# ATmega32C1 device description
Architecture: AVR8; Family: megaAVR
Registers are 8-bit, access not given, no defined reset value unless marked. A register's access mark holds for its fields unless they carry their own. Offsets are from the block's base; [hi:lo] are bit positions.

## LINUART — Local Interconnect Network
Instances: LINUART 0x00
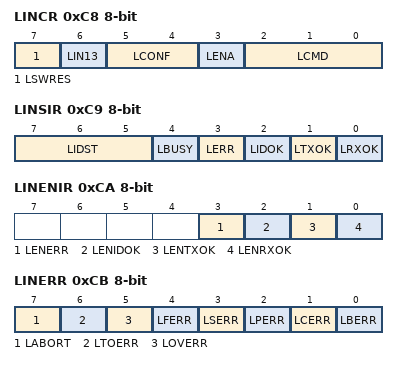
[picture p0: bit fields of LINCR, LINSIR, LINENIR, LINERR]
0xC8 LINCR — LIN Control Register
  [7] LSWRES — Software Reset
  [6] LIN13 — LIN Standard
  [5:4] LCONF — LIN Configuration bits
  [3] LENA — LIN or UART Enable
  [2:0] LCMD — LIN Command and Mode bits
0xC9 LINSIR — LIN Status and Interrupt Register
  [7:5] LIDST — Identifier Status bits
  [4] LBUSY — Busy Signal
  [3] LERR — Error Interrupt
  [2] LIDOK — Identifier Interrupt
  [1] LTXOK — Transmit Performed Interrupt
  [0] LRXOK — Receive Performed Interrupt
0xCA LINENIR — LIN Enable Interrupt Register
  [3] LENERR — Enable Error Interrupt
  [2] LENIDOK — Enable Identifier Interrupt
  [1] LENTXOK — Enable Transmit Performed Interrupt
  [0] LENRXOK — Enable Receive Performed Interrupt
0xCB LINERR — LIN Error Register
  [7] LABORT — Abort Flag
  [6] LTOERR — Frame Time Out Error Flag
  [5] LOVERR — Overrun Error Flag
  [4] LFERR — Framing Error Flag
  [3] LSERR — Synchronization Error Flag
  [2] LPERR — Parity Error Flag
  [1] LCERR — Checksum Error Flag
  [0] LBERR — Bit Error Flag
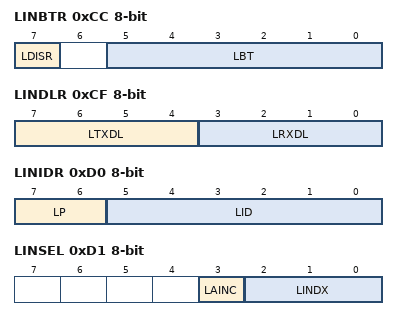
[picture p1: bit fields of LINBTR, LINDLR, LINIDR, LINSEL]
0xCC LINBTR — LIN Bit Timing Register
  [7] LDISR — Disable Bit Timing Resynchronization
  [5:0] LBT — LIN Bit Timing bits
0xCD LINBRR 16-bit — LIN Baud Rate Register
  [11:0] LDIV
0xCF LINDLR — LIN Data Length Register
  [7:4] LTXDL — LIN Transmit Data Length bits
  [3:0] LRXDL — LIN Receive Data Length bits
0xD0 LINIDR — LIN Identifier Register
  [7:6] LP — Parity bits
  [5:0] LID — Identifier bit 5 or Data Length bits
0xD1 LINSEL — LIN Data Buffer Selection Register
  [3] LAINC — Auto Increment of Data Buffer Index (Active Low)
  [2:0] LINDX — FIFO LIN Data Buffer Index bits
0xD2 LINDAT — LIN Data Register
  [7:0] LDATA

## SPI — Serial Peripheral Interface
Instances: SPI 0x00
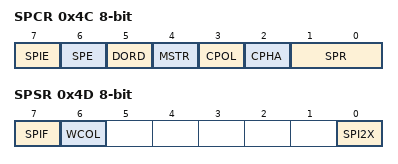
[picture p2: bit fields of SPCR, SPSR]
0x4C SPCR — SPI Control Register
  [7] SPIE — SPI Interrupt Enable
  [6] SPE — SPI Enable
  [5] DORD — Data Order
  [4] MSTR — Master/Slave Select
  [3] CPOL — Clock polarity
  [2] CPHA — Clock Phase
  [1:0] SPR — SPI Clock Rate Selects
    0=FOSC_4; 1=FOSC_16; 2=FOSC_64; 3=FOSC_128; 4=FOSC_2; 5=FOSC_8; 6=FOSC_32; 7=FOSC_64
0x4D SPSR — SPI Status Register
  [7] SPIF — SPI Interrupt Flag
  [6] WCOL — Write Collision Flag
  [0] SPI2X — Double SPI Speed Bit
0x4E SPDR — SPI Data Register
  [7:0] SPDR — SPI Data bits

## WDT — Watchdog Timer
Instances: WDT 0x00
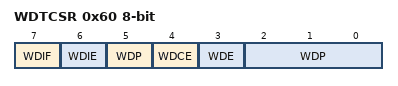
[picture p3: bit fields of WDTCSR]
0x60 WDTCSR — Watchdog Timer Control Register
  [7] WDIF — Watchdog Timeout Interrupt Flag
  [6] WDIE — Watchdog Timeout Interrupt Enable
  [4] WDCE — Watchdog Change Enable
  [3] WDE — Watch Dog Enable
  [5,2:0] WDP — Watchdog Timer Prescaler Bits
    0=OSCILLATOR_CYCLES_2K; 1=OSCILLATOR_CYCLES_4K; 2=OSCILLATOR_CYCLES_8K; 3=OSCILLATOR_CYCLES_16K; 4=OSCILLATOR_CYCLES_32K; 5=OSCILLATOR_CYCLES_64K; 6=OSCILLATOR_CYCLES_128K; 7=OSCILLATOR_CYCLES_256K; 8=OSCILLATOR_CYCLES_512K; 9=OSCILLATOR_CYCLES_1024K

## EXINT — External Interrupts
Instances: EXINT 0x00
0x3B PCIFR — Pin Change Interrupt Flag Register
  [3:0] PCIF — Pin Change Interrupt Flags
0x3C EIFR — External Interrupt Flag Register
  [3:0] INTF — External Interrupt Flags
0x3D EIMSK — External Interrupt Mask Register
  [3:0] INT — External Interrupt Request 3 Enable
0x68 PCICR — Pin Change Interrupt Control Register
  [3:0] PCIE — Pin Change Interrupt Enables
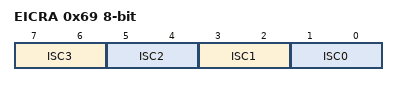
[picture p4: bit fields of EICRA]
0x69 EICRA — External Interrupt Control Register
  [all] fields
    0=LOW_LEVEL_OF_INTX; 1=ANY_LOGICAL_CHANGE_OF_INTX; 2=FALLING_EDGE_OF_INTX; 3=RISING_EDGE_OF_INTX
  [7:6] ISC3 — External Interrupt Sense Control Bit
  [5:4] ISC2 — External Interrupt Sense Control Bit
  [3:2] ISC1 — External Interrupt Sense Control 1 Bits
  [1:0] ISC0 — External Interrupt Sense Control 0 Bits
0x6A PCMSK0 — Pin Change Mask Register 0
  [7:0] PCINT — Pin Change Enable Masks
0x6B PCMSK1 — Pin Change Mask Register 1
  [7:0] PCINT (bit 8 of the value upward) — Pin Change Enable Masks
0x6C PCMSK2 — Pin Change Mask Register 2
  [7:0] PCINT (bit 16 of the value upward) — Pin Change Enable Masks
0x6D PCMSK3 — Pin Change Mask Register 3
  [2:0] PCINT (bit 24 of the value upward) — Pin Change Enable Masks

## EEPROM
Instances: EEPROM 0x00
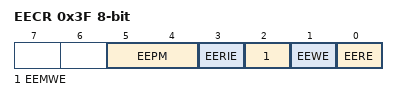
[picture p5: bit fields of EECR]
0x3F EECR — EEPROM Control Register
  [5:4] EEPM — EEPROM Programming mode
    0=ERASE_AND_WRITE_IN_ONE_OPERATION; 1=ERASE_ONLY; 2=WRITE_ONLY
  [3] EERIE — EEPROM Ready Interrupt Enable
  [2] EEMWE — EEPROM Master Write Enable
  [1] EEWE — EEPROM Write Enable
  [0] EERE — EEPROM Read Enable
0x40 EEDR — EEPROM Data Register
  [7:0] EEDR — EEPROM Data bits
0x41 EEAR 16-bit — EEPROM Read/Write Access
  [9:0] EEAR — EEPROM Address bits
